# M061 register map
File version: 2.0.2.1
CPU: 
Registers are 32-bit, read-write, reset 0x0 unless marked. A register's access mark holds for its fields unless they carry their own. Offsets are from the block's base; [hi:lo] are bit positions; {n}, {i} and the like mark numbered series.

## DSAD0 — 16-bit Deita sigma AD converter
Base 0x44067000
Same registers: DSAD1 0x44068000, DSAD2 0x44069000
0x00 CLK — DSAD Conversion Clock Setting Register
  [2:0] ADCLK
0x04 CR0 — DSAD Control Register 0
  [1:0] ADRST wo
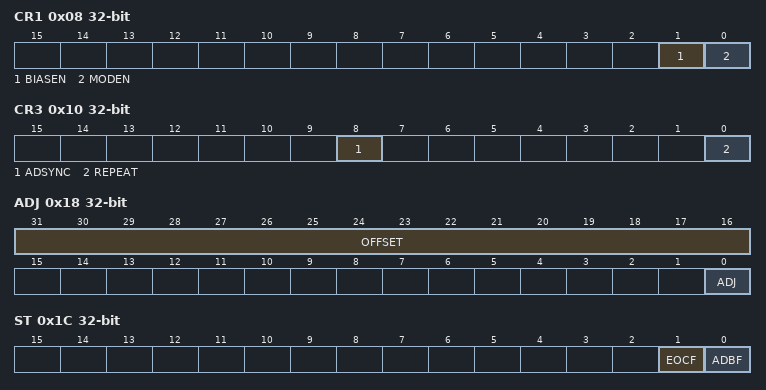
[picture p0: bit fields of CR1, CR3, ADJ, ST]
0x08 CR1 — DSAD Control Register 1
  [1] BIASEN, [0] MODEN
0x0C CR2 — DSAD Control Register 2
  [0] ADS wo
0x10 CR3 — DSAD Control Register 3
  [8] ADSYNC, [0] REPEAT
0x14 CR4 — DSAD Control Register 4
  [2:0] DSGAIN
0x18 ADJ — DSAD Adjust Register
  [31:16] OFFSET, [0] ADJ
0x1C ST — DSAD Status Register
  [1] EOCF ro, [0] ADBF ro
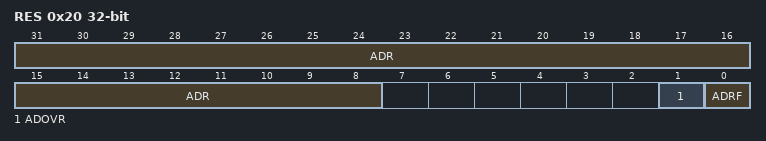
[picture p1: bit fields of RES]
0x20 RES — DSAD Result Register
  [31:8] ADR ro, [1] ADOVR ro, [0] ADRF ro

## TEMP — Temperature Sensor
Base 0x4005D000
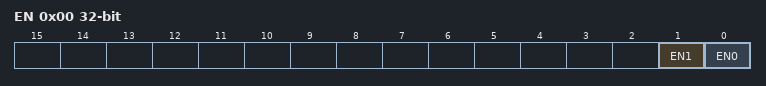
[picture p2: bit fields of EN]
0x00 EN — TEMP Enable Register
  [1] EN1, [0] EN0
0x04 CR — TEMP Control Registe
  [0] CR0

## LVD — Low Voltage detector control register
Base 0x400F4000
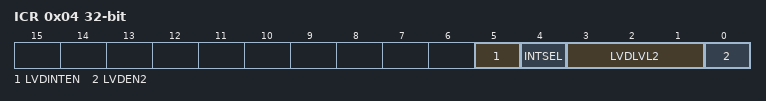
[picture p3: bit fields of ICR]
0x04 ICR — LVD-NMI Control Register
  [5] LVDINTEN, [4] INTSEL, [3:1] LVDLVL2, [0] LVDEN2
0x08 SR — LVD Status Control Register
  [1] LVDST2 ro

## RTC — Real Time Clock (RTC)
Base 0x400CC000
0x00 SECR 8-bit (reset mask 0x80) — RTC Sec setting register
  [6:0] SE
0x01 MINR 8-bit (reset mask 0x80) — RTC Min settging register
  [6:0] MI
0x02 HOURR 8-bit (reset mask 0xC0) — RTC Hour setting register
  [5:0] HO
0x04 DAYR 8-bit (reset mask 0xF8) — RTC Day setting register
  [2:0] WE
0x05 DATER 8-bit (reset mask 0xC0) — RTC Date setting register
  [5:0] DA
0x06 MONTHR 8-bit (reset mask 0xE0) — RTC Month settging register PAGE0
  [4:0] MO
0x07 YEARR_A 8-bit reset not defined — RTC Year setting register PAGE0
  [7:0] YE
0x07 YEARR_B 8-bit (reset mask 0xFC) (RTC_YEARR view) — RTC Leap year register PAGE1
  [1:0] LEAP
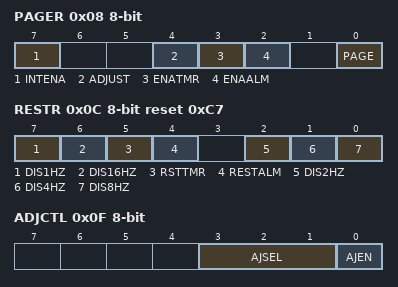
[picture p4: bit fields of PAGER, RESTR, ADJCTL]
0x08 PAGER 8-bit (reset mask 0xF3) — RTC Page register
  [7] INTENA, [4] ADJUST, [3] ENATMR, [2] ENAALM, [0] PAGE
0x0C RESTR 8-bit reset 0xC7 — RTC Reset register
  [7] DIS1HZ, [6] DIS16HZ, [5] RSTTMR, [4] RESTALM, [2] DIS2HZ, [1] DIS4HZ, [0] DIS8HZ
0x0E PROTECT 8-bit reset 0xC1 — RTC clock adjust control register
0x0F ADJCTL 8-bit — RTC protect register
  [3:1] AJSEL, [0] AJEN
0x10 ADJDAT 16-bit — RTC clock adjust data register
  [8:0] ADJDAT

## LCD — LCD Driver (LCD)
Base 0x4006E000
0x00 EN — Enable register
  [0] LCDE
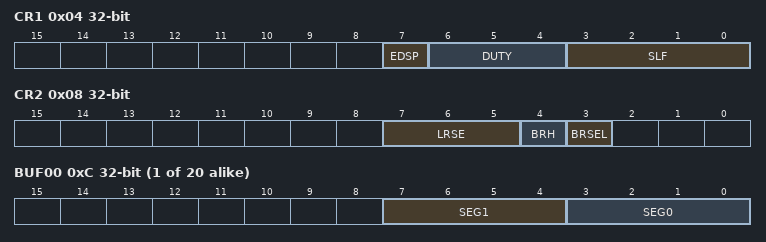
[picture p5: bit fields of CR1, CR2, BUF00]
0x04 CR1 — Control register 1
  [7] EDSP, [6:4] DUTY, [3:0] SLF
0x08 CR2 — Control register 2
  [7:5] LRSE, [4] BRH, [3] BRSEL
{0xC+4i} BUF{i:02} (i=0..19) — Buffer register {i:02}
  [7:4] SEG{2i+1}, [3:0] SEG{2i}

## FC — Flash Control (FC)
Base 0x41FFF000
0x10 SECBIT reset 0x1 — FC Security Bit Register
  [0] SECBIT
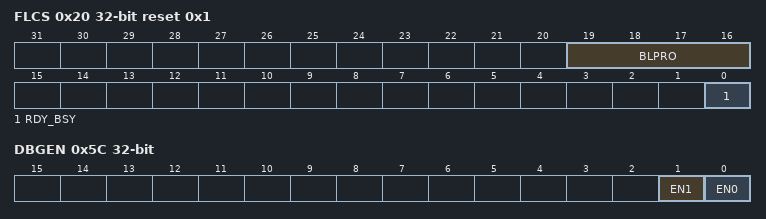
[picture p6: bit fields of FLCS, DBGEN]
0x20 FLCS ro reset 0x1 (reset mask 0xFFF0FFFF) — FC Flash Control Register
  [19:16] BLPRO, [0] RDY_BSY
0x5C DBGEN — FC Debug enable monitor Register
  [1] EN1 ro, [0] EN0 ro

## PCE — Power Calculation Engine (PCE)
Base 0x4406F000
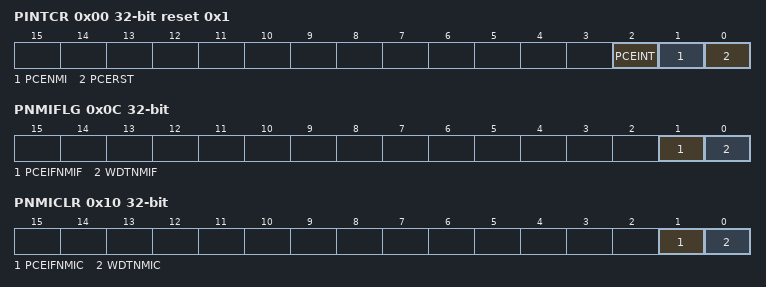
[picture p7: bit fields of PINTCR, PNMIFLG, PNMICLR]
0x00 PINTCR reset 0x1 — PCE core interrupt control
  [2] PCEINT wo, [1] PCENMI wo, [0] PCERST
0x04 MINTCR — Interrupt control to the main core
  [0] MAININT wo
0x08 PCLKCR — PCE core clock control)
  [0] PCECLK
0x0C PNMIFLG — PCE core NMI event flag)
  [1] PCEIFNMIF ro, [0] WDTNMIF ro
0x10 PNMICLR — PCE core NMI event clear)
  [1] PCEIFNMIC wo, [0] WDTNMIC wo

## CG — Clock Generator (CG)
Base 0x400F3000
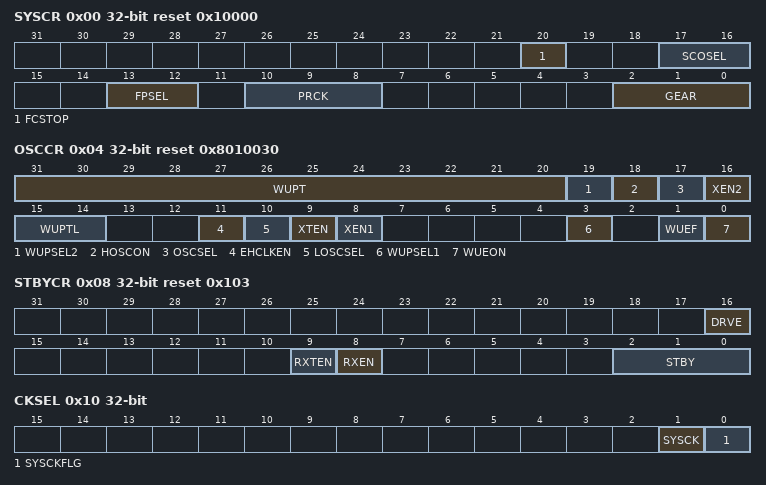
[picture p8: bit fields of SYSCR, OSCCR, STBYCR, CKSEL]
0x00 SYSCR reset 0x10000 — System Control Register
  [20] FCSTOP, [17:16] SCOSEL, [13:12] FPSEL, [10:8] PRCK, [2:0] GEAR
0x04 OSCCR reset 0x8010030 — Oscillation Control Register
  [31:20] WUPT, [19] WUPSEL2, [18] HOSCON, [17] OSCSEL, [16] XEN2, [15:14] WUPTL, [11] EHCLKEN, [10] LOSCSEL, [9] XTEN, [8] XEN1, [3] WUPSEL1, [1] WUEF ro, [0] WUEON wo
0x08 STBYCR reset 0x103 — Standby Control Register
  [16] DRVE, [9] RXTEN, [8] RXEN, [2:0] STBY
0x0C EHCLKSEL reset 0x721E — External High-speed clock select register
  [0] EHCLKSEL
0x10 CKSEL — System Clock Selection Register
  [1] SYSCK, [0] SYSCKFLG ro
0x14 ICRCG wo — CG Interrupt Request Clear Register
  [4:0] ICRCG
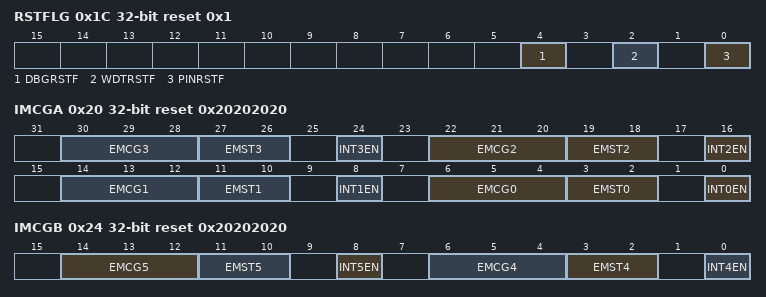
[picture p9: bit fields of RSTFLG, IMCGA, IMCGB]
0x1C RSTFLG reset 0x1 — Reset Flag Register
  [4] DBGRSTF, [2] WDTRSTF, [0] PINRSTF
0x20 IMCGA reset 0x20202020 — CG Interrupt Mode Control Register A
  [8n+6:8n+4] EMCG{n} (n=0..3), [8n+3:8n+2] EMST{n} ro (n=0..3), [8n] INT{n}EN (n=0..3)
0x24 IMCGB reset 0x20202020 — CG Interrupt Mode Control Register B
  [14:12] EMCG5, [11:10] EMST5 ro, [8] INT5EN, [6:4] EMCG4, [3:2] EMST4 ro, [0] INT4EN
